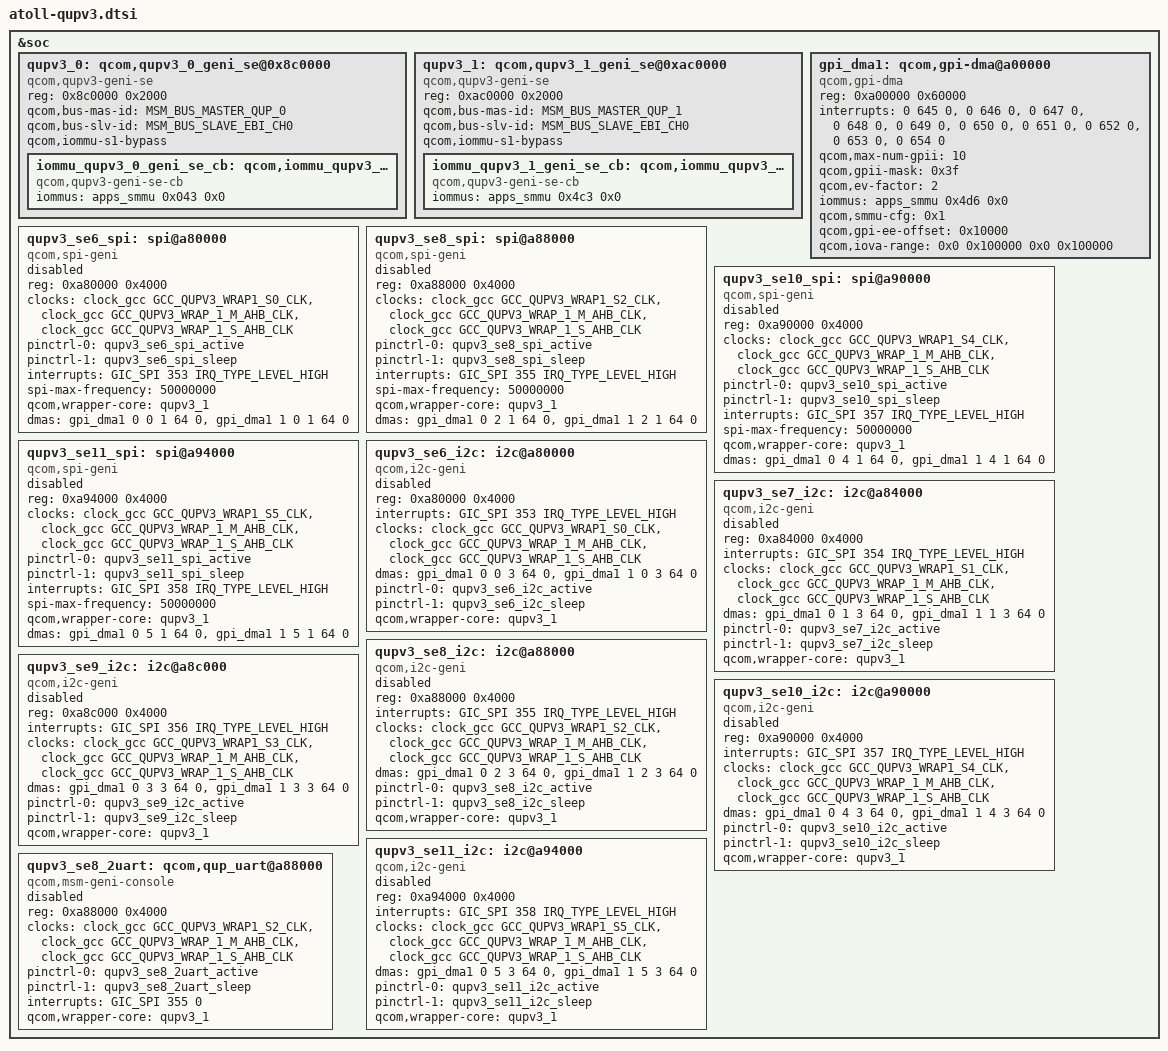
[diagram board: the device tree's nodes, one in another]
/* Copyright (c) 2019, The Linux Foundation. All rights reserved.
 *
 * This program is free software; you can redistribute it and/or modify
 * it under the terms of the GNU General Public License version 2 and
 * only version 2 as published by the Free Software Foundation.
 *
 * This program is distributed in the hope that it will be useful,
 * but WITHOUT ANY WARRANTY; without even the implied warranty of
 * MERCHANTABILITY or FITNESS FOR A PARTICULAR PURPOSE.  See the
 * GNU General Public License for more details.
 */

#include <dt-bindings/msm/msm-bus-ids.h>

&soc {

	/* QUPv3 North instances */
	qupv3_0: qcom,qupv3_0_geni_se@0x8c0000 {
		compatible = "qcom,qupv3-geni-se";
		reg = <0x8c0000 0x2000>;
		qcom,bus-mas-id = <MSM_BUS_MASTER_QUP_0>;
		qcom,bus-slv-id = <MSM_BUS_SLAVE_EBI_CH0>;
		qcom,iommu-s1-bypass;

		iommu_qupv3_0_geni_se_cb: qcom,iommu_qupv3_0_geni_se_cb {
			compatible = "qcom,qupv3-geni-se-cb";
			iommus = <&apps_smmu 0x043 0x0>;
		};
	};

	/* QUPv3 South Instances */
	qupv3_1: qcom,qupv3_1_geni_se@0xac0000 {
		compatible = "qcom,qupv3-geni-se";
		reg = <0xac0000 0x2000>;
		qcom,bus-mas-id = <MSM_BUS_MASTER_QUP_1>;
		qcom,bus-slv-id = <MSM_BUS_SLAVE_EBI_CH0>;
		qcom,iommu-s1-bypass;

		iommu_qupv3_1_geni_se_cb: qcom,iommu_qupv3_1_geni_se_cb {
			compatible = "qcom,qupv3-geni-se-cb";
			iommus = <&apps_smmu 0x4c3 0x0>;
		};
	};

	/* GPI */
	gpi_dma1: qcom,gpi-dma@a00000 {
		#dma-cells = <5>;
		compatible = "qcom,gpi-dma";
		reg = <0xa00000 0x60000>;
		reg-names = "gpi-top";
		interrupts = <0 645 0>, <0 646 0>, <0 647 0>, <0 648 0>,
			     <0 649 0>, <0 650 0>, <0 651 0>, <0 652 0>,
			     <0 653 0>, <0 654 0>;
		qcom,max-num-gpii = <10>;
		qcom,gpii-mask = <0x3f>;
		qcom,ev-factor = <2>;
		iommus = <&apps_smmu 0x4d6 0x0>;
		qcom,smmu-cfg = <0x1>;
		qcom,gpi-ee-offset = <0x10000>;
		qcom,iova-range = <0x0 0x100000 0x0 0x100000>;
		status = "ok";
	};

	/* SPI */
	qupv3_se6_spi: spi@a80000 {
		compatible = "qcom,spi-geni";
		#address-cells = <1>;
		#size-cells = <0>;
		reg = <0xa80000 0x4000>;
		reg-names = "se_phys";
		clock-names = "se-clk", "m-ahb", "s-ahb";
		clocks = <&clock_gcc GCC_QUPV3_WRAP1_S0_CLK>,
			<&clock_gcc GCC_QUPV3_WRAP_1_M_AHB_CLK>,
			<&clock_gcc GCC_QUPV3_WRAP_1_S_AHB_CLK>;
		pinctrl-names = "default", "sleep";
		pinctrl-0 = <&qupv3_se6_spi_active>;
		pinctrl-1 = <&qupv3_se6_spi_sleep>;
		interrupts = <GIC_SPI 353 IRQ_TYPE_LEVEL_HIGH>;
		spi-max-frequency = <50000000>;
		qcom,wrapper-core = <&qupv3_1>;
		dmas = <&gpi_dma1 0 0 1 64 0>,
			<&gpi_dma1 1 0 1 64 0>;
		dma-names = "tx", "rx";
		status = "disabled";
	};

	qupv3_se8_spi: spi@a88000 {
		compatible = "qcom,spi-geni";
		#address-cells = <1>;
		#size-cells = <0>;
		reg = <0xa88000 0x4000>;
		reg-names = "se_phys";
		clock-names = "se-clk", "m-ahb", "s-ahb";
		clocks = <&clock_gcc GCC_QUPV3_WRAP1_S2_CLK>,
			<&clock_gcc GCC_QUPV3_WRAP_1_M_AHB_CLK>,
			<&clock_gcc GCC_QUPV3_WRAP_1_S_AHB_CLK>;
		pinctrl-names = "default", "sleep";
		pinctrl-0 = <&qupv3_se8_spi_active>;
		pinctrl-1 = <&qupv3_se8_spi_sleep>;
		interrupts = <GIC_SPI 355 IRQ_TYPE_LEVEL_HIGH>;
		spi-max-frequency = <50000000>;
		qcom,wrapper-core = <&qupv3_1>;
		dmas = <&gpi_dma1 0 2 1 64 0>,
			<&gpi_dma1 1 2 1 64 0>;
		dma-names = "tx", "rx";
		status = "disabled";
	};

	qupv3_se10_spi: spi@a90000 {
		compatible = "qcom,spi-geni";
		#address-cells = <1>;
		#size-cells = <0>;
		reg = <0xa90000 0x4000>;
		reg-names = "se_phys";
		clock-names = "se-clk", "m-ahb", "s-ahb";
		clocks = <&clock_gcc GCC_QUPV3_WRAP1_S4_CLK>,
			<&clock_gcc GCC_QUPV3_WRAP_1_M_AHB_CLK>,
			<&clock_gcc GCC_QUPV3_WRAP_1_S_AHB_CLK>;
		pinctrl-names = "default", "sleep";
		pinctrl-0 = <&qupv3_se10_spi_active>;
		pinctrl-1 = <&qupv3_se10_spi_sleep>;
		interrupts = <GIC_SPI 357 IRQ_TYPE_LEVEL_HIGH>;
		spi-max-frequency = <50000000>;
		qcom,wrapper-core = <&qupv3_1>;
		dmas = <&gpi_dma1 0 4 1 64 0>,
			<&gpi_dma1 1 4 1 64 0>;
		dma-names = "tx", "rx";
		status = "disabled";
	};

	qupv3_se11_spi: spi@a94000 {
		compatible = "qcom,spi-geni";
		#address-cells = <1>;
		#size-cells = <0>;
		reg = <0xa94000 0x4000>;
		reg-names = "se_phys";
		clock-names = "se-clk", "m-ahb", "s-ahb";
		clocks = <&clock_gcc GCC_QUPV3_WRAP1_S5_CLK>,
			<&clock_gcc GCC_QUPV3_WRAP_1_M_AHB_CLK>,
			<&clock_gcc GCC_QUPV3_WRAP_1_S_AHB_CLK>;
		pinctrl-names = "default", "sleep";
		pinctrl-0 = <&qupv3_se11_spi_active>;
		pinctrl-1 = <&qupv3_se11_spi_sleep>;
		interrupts = <GIC_SPI 358 IRQ_TYPE_LEVEL_HIGH>;
		spi-max-frequency = <50000000>;
		qcom,wrapper-core = <&qupv3_1>;
		dmas = <&gpi_dma1 0 5 1 64 0>,
			<&gpi_dma1 1 5 1 64 0>;
		dma-names = "tx", "rx";
		status = "disabled";
	};

	/* I2C */
	qupv3_se6_i2c: i2c@a80000 {
		compatible = "qcom,i2c-geni";
		reg = <0xa80000 0x4000>;
		interrupts = <GIC_SPI 353 IRQ_TYPE_LEVEL_HIGH>;
		#address-cells = <1>;
		#size-cells = <0>;
		clock-names = "se-clk", "m-ahb", "s-ahb";
		clocks = <&clock_gcc GCC_QUPV3_WRAP1_S0_CLK>,
			<&clock_gcc GCC_QUPV3_WRAP_1_M_AHB_CLK>,
			<&clock_gcc GCC_QUPV3_WRAP_1_S_AHB_CLK>;
		dmas = <&gpi_dma1 0 0 3 64 0>,
			<&gpi_dma1 1 0 3 64 0>;
		dma-names = "tx", "rx";
		pinctrl-names = "default", "sleep";
		pinctrl-0 = <&qupv3_se6_i2c_active>;
		pinctrl-1 = <&qupv3_se6_i2c_sleep>;
		qcom,wrapper-core = <&qupv3_1>;
		status = "disabled";
	};

	qupv3_se7_i2c: i2c@a84000 {
		compatible = "qcom,i2c-geni";
		reg = <0xa84000 0x4000>;
		interrupts = <GIC_SPI 354 IRQ_TYPE_LEVEL_HIGH>;
		#address-cells = <1>;
		#size-cells = <0>;
		clock-names = "se-clk", "m-ahb", "s-ahb";
		clocks = <&clock_gcc GCC_QUPV3_WRAP1_S1_CLK>,
			<&clock_gcc GCC_QUPV3_WRAP_1_M_AHB_CLK>,
			<&clock_gcc GCC_QUPV3_WRAP_1_S_AHB_CLK>;
		dmas = <&gpi_dma1 0 1 3 64 0>,
			<&gpi_dma1 1 1 3 64 0>;
		dma-names = "tx", "rx";
		pinctrl-names = "default", "sleep";
		pinctrl-0 = <&qupv3_se7_i2c_active>;
		pinctrl-1 = <&qupv3_se7_i2c_sleep>;
		qcom,wrapper-core = <&qupv3_1>;
		status = "disabled";
	};

	qupv3_se8_i2c: i2c@a88000 {
		compatible = "qcom,i2c-geni";
		reg = <0xa88000 0x4000>;
		interrupts = <GIC_SPI 355 IRQ_TYPE_LEVEL_HIGH>;
		#address-cells = <1>;
		#size-cells = <0>;
		clock-names = "se-clk", "m-ahb", "s-ahb";
		clocks = <&clock_gcc GCC_QUPV3_WRAP1_S2_CLK>,
			<&clock_gcc GCC_QUPV3_WRAP_1_M_AHB_CLK>,
			<&clock_gcc GCC_QUPV3_WRAP_1_S_AHB_CLK>;
		dmas = <&gpi_dma1 0 2 3 64 0>,
			<&gpi_dma1 1 2 3 64 0>;
		dma-names = "tx", "rx";
		pinctrl-names = "default", "sleep";
		pinctrl-0 = <&qupv3_se8_i2c_active>;
		pinctrl-1 = <&qupv3_se8_i2c_sleep>;
		qcom,wrapper-core = <&qupv3_1>;
		status = "disabled";
	};

	qupv3_se9_i2c: i2c@a8c000 {
		compatible = "qcom,i2c-geni";
		reg = <0xa8c000 0x4000>;
		interrupts = <GIC_SPI 356 IRQ_TYPE_LEVEL_HIGH>;
		#address-cells = <1>;
		#size-cells = <0>;
		clock-names = "se-clk", "m-ahb", "s-ahb";
		clocks = <&clock_gcc GCC_QUPV3_WRAP1_S3_CLK>,
			<&clock_gcc GCC_QUPV3_WRAP_1_M_AHB_CLK>,
			<&clock_gcc GCC_QUPV3_WRAP_1_S_AHB_CLK>;
		dmas = <&gpi_dma1 0 3 3 64 0>,
			<&gpi_dma1 1 3 3 64 0>;
		dma-names = "tx", "rx";
		pinctrl-names = "default", "sleep";
		pinctrl-0 = <&qupv3_se9_i2c_active>;
		pinctrl-1 = <&qupv3_se9_i2c_sleep>;
		qcom,wrapper-core = <&qupv3_1>;
		status = "disabled";
	};

	qupv3_se10_i2c: i2c@a90000 {
		compatible = "qcom,i2c-geni";
		reg = <0xa90000 0x4000>;
		interrupts = <GIC_SPI 357 IRQ_TYPE_LEVEL_HIGH>;
		#address-cells = <1>;
		#size-cells = <0>;
		clock-names = "se-clk", "m-ahb", "s-ahb";
		clocks = <&clock_gcc GCC_QUPV3_WRAP1_S4_CLK>,
			<&clock_gcc GCC_QUPV3_WRAP_1_M_AHB_CLK>,
			<&clock_gcc GCC_QUPV3_WRAP_1_S_AHB_CLK>;
		dmas = <&gpi_dma1 0 4 3 64 0>,
			<&gpi_dma1 1 4 3 64 0>;
		dma-names = "tx", "rx";
		pinctrl-names = "default", "sleep";
		pinctrl-0 = <&qupv3_se10_i2c_active>;
		pinctrl-1 = <&qupv3_se10_i2c_sleep>;
		qcom,wrapper-core = <&qupv3_1>;
		status = "disabled";
	};

	qupv3_se11_i2c: i2c@a94000 {
		compatible = "qcom,i2c-geni";
		reg = <0xa94000 0x4000>;
		interrupts = <GIC_SPI 358 IRQ_TYPE_LEVEL_HIGH>;
		#address-cells = <1>;
		#size-cells = <0>;
		clock-names = "se-clk", "m-ahb", "s-ahb";
		clocks = <&clock_gcc GCC_QUPV3_WRAP1_S5_CLK>,
			<&clock_gcc GCC_QUPV3_WRAP_1_M_AHB_CLK>,
			<&clock_gcc GCC_QUPV3_WRAP_1_S_AHB_CLK>;
		dmas = <&gpi_dma1 0 5 3 64 0>,
			<&gpi_dma1 1 5 3 64 0>;
		dma-names = "tx", "rx";
		pinctrl-names = "default", "sleep";
		pinctrl-0 = <&qupv3_se11_i2c_active>;
		pinctrl-1 = <&qupv3_se11_i2c_sleep>;
		qcom,wrapper-core = <&qupv3_1>;
		status = "disabled";
	};

	qupv3_se8_2uart: qcom,qup_uart@a88000 {
		compatible = "qcom,msm-geni-console";
		reg = <0xa88000 0x4000>;
		reg-names = "se_phys";
		clock-names = "se-clk", "m-ahb", "s-ahb";
		clocks = <&clock_gcc GCC_QUPV3_WRAP1_S2_CLK>,
			<&clock_gcc GCC_QUPV3_WRAP_1_M_AHB_CLK>,
			<&clock_gcc GCC_QUPV3_WRAP_1_S_AHB_CLK>;
		pinctrl-names = "default", "sleep";
		pinctrl-0 = <&qupv3_se8_2uart_active>;
		pinctrl-1 = <&qupv3_se8_2uart_sleep>;
		interrupts = <GIC_SPI 355 0>;
		qcom,wrapper-core = <&qupv3_1>;
		status = "disabled";
	};
};

